AUTOSAR XML (schema 4-0-3)
package /ExamplePkg
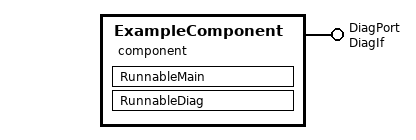
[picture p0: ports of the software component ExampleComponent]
  sw component type ExampleComponent
    provide port DiagPort: provided-interface=DiagIf
    internal behavior ExampleComponent_Internal
      runnable RunnableMain
      runnable RunnableDiag
      timing event Main_5ms: period=0.005, start-on-event=RunnableMain
      data received event DiagDataRx: data=DiagData, start-on-event=RunnableDiag
package /EcuConfig
  ecuc module configuration ExampleEcuC: definition=EcuC, MaxNvmBlocks=128, Variant=Prod
